# STM32H523 register map
File version: 1.3
CPU: CM33 r0p0, little endian, MPU, FPU, 4 interrupt priority bits
Registers are 32-bit, read-write, reset 0x0 unless marked. A register's access mark holds for its fields unless they carry their own. Offsets are from the block's base; [hi:lo] are bit positions; 'fields as' and 'values as' point back to an identical list.

## CRS — CRS address block description
Base 0x40006000
Same registers: CRS_S 0x50006000
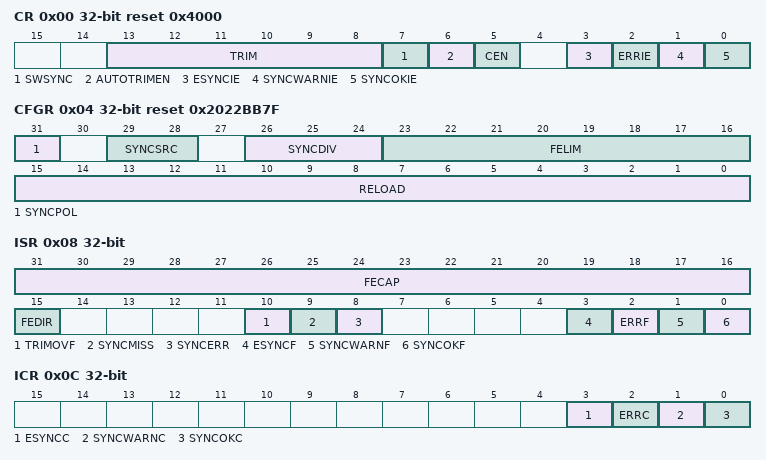
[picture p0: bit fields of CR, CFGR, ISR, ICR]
0x00 CR reset 0x4000 — CRS control register
  [13:8] TRIM — HSI48 oscillator smooth trimming
  [7] SWSYNC — Generate software SYNC event
    1=Sync (A software sync is generated)
  [6] AUTOTRIMEN — Automatic trimming enable
    0=Disabled (Automatic trimming disabled); 1=Enabled (Automatic trimming enabled)
  [5] CEN — Frequency error counter enable
    0=Disabled (Frequency error counter disabled); 1=Enabled (Frequency error counter enabled)
  [3] ESYNCIE — Expected SYNC interrupt enable
    0=Disabled (Interrupt disabled); 1=Enabled (Interrupt enabled)
  [2] ERRIE — Synchronization or trimming error interrupt enable
    values as ESYNCIE
  [1] SYNCWARNIE — SYNC warning interrupt enable
    values as ESYNCIE
  [0] SYNCOKIE — SYNC event OK interrupt enable
    values as ESYNCIE
0x04 CFGR reset 0x2022BB7F — CRS configuration register
  [31] SYNCPOL — SYNC polarity selection
    0=RisingEdge (SYNC active on rising edge); 1=FallingEdge (SYNC active on falling edge)
  [29:28] SYNCSRC — SYNC signal source selection
    0=GPIO_AF (GPIO AF (crs_sync_in_1) selected as SYNC signal source); 1=LSE (LSE (crs_sync_in_2) selected as SYNC signal source); 2=USB_SOF (USB SOF (crs_sync_in_3) selected as SYNC signal source)
  [26:24] SYNCDIV — SYNC divider
    0=Div1 (SYNC not divided); 1=Div2 (SYNC divided by 2); 2=Div4 (SYNC divided by 4); 3=Div8 (SYNC divided by 8); 4=Div16 (SYNC divided by 16); 5=Div32 (SYNC divided by 32); 6=Div64 (SYNC divided by 64); 7=Div128 (SYNC divided by 128)
  [23:16] FELIM — Frequency error limit
  [15:0] RELOAD — Counter reload value
0x08 ISR ro — CRS interrupt and status register
  [31:16] FECAP — Frequency error capture
  [15] FEDIR — Frequency error direction
    0=UpCounting (Error in up-counting direction); 1=DownCounting (Error in down-counting direction)
  [10] TRIMOVF — Trimming overflow or underflow
    0=NotSignaled (Signal not set); 1=Signaled (Signal set)
  [9] SYNCMISS — SYNC missed
    0=NotSignaled (Signal not set); 1=Signaled (Signal set)
  [8] SYNCERR — SYNC error
    0=NotSignaled (Signal not set); 1=Signaled (Signal set)
  [3] ESYNCF — Expected SYNC flag
    0=NotSignaled (Signal not set); 1=Signaled (Signal set)
  [2] ERRF — Error flag
    0=NotSignaled (Signal not set); 1=Signaled (Signal set)
  [1] SYNCWARNF — SYNC warning flag
    0=NotSignaled (Signal not set); 1=Signaled (Signal set)
  [0] SYNCOKF — SYNC event OK flag
    0=NotSignaled (Signal not set); 1=Signaled (Signal set)
0x0C ICR — CRS interrupt flag clear register
  [all] fields
    1=Clear flag
  [3] ESYNCC — Expected SYNC clear flag
  [2] ERRC — Error clear flag
  [1] SYNCWARNC — SYNC warning clear flag
  [0] SYNCOKC — SYNC event OK clear flag

## DCACHE — DCACHE register block
Base 0x40031400
Same registers: DCACHE_S 0x50031400
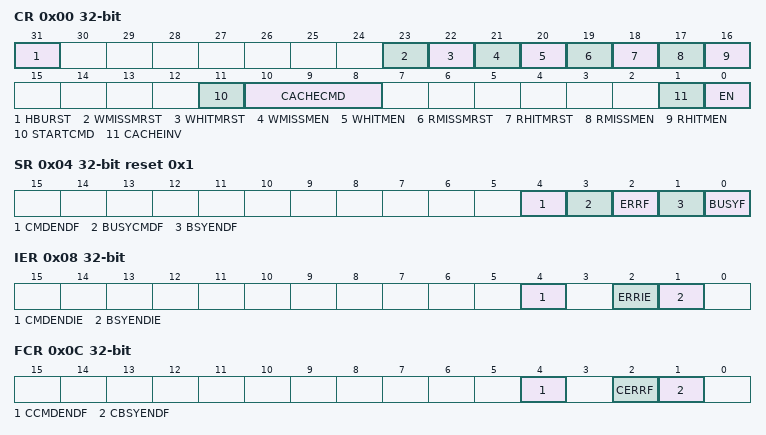
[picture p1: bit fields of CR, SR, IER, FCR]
0x00 CR — DCACHE control register
  [31] HBURST — output burst type for cache master port read accesses
  [23] WMISSMRST — write-miss monitor reset
  [22] WHITMRST — write-hit monitor reset
  [21] WMISSMEN — write-miss monitor enable
  [20] WHITMEN — write-hit monitor enable
  [19] RMISSMRST — read-miss monitor reset
  [18] RHITMRST — read-hit monitor reset
  [17] RMISSMEN — read-miss monitor enable
  [16] RHITMEN — read-hit monitor enable
  [11] STARTCMD wo — starts maintenance command (maintenance operation defined in CACHECMD).
  [10:8] CACHECMD — cache command maintenance operation (cleans and/or invalidates an address range)
  [1] CACHEINV wo — full cache invalidation
  [0] EN — enable
0x04 SR ro reset 0x1 — DCACHE status register
  [4] CMDENDF — command end flag
  [3] BUSYCMDF — command busy flag
  [2] ERRF — cache error flag
  [1] BSYENDF — full invalidate busy end flag
  [0] BUSYF — full invalidate busy flag
0x08 IER — DCACHE interrupt enable register
  [4] CMDENDIE — interrupt enable on command end
  [2] ERRIE — interrupt enable on cache error
  [1] BSYENDIE — interrupt enable on busy end
0x0C FCR wo — DCACHE flag clear register
  [4] CCMDENDF — clear command end flag
  [2] CERRF — clear cache error flag
  [1] CBSYENDF — clear full invalidate busy end flag
0x10 RHMONR ro — DCACHE read-hit monitor register
  [31:0] RHITMON — cache read-hit monitor counter
0x14 RMMONR ro — DCACHE read-miss monitor register
  [15:0] RMISSMON — cache read-miss monitor counter
0x20 WHMONR ro — DCACHE write-hit monitor register
  [31:0] WHITMON — cache write-hit monitor counter
0x24 WMMONR ro — DCACHE write-miss monitor register
  [15:0] WMISSMON — cache write-miss monitor counter
0x28 CMDRSADDRR — DCACHE command range start address register
  [31:4] CMDSTARTADDR — start address of range to which the cache maintenance command specified in DCACHE_CR.
0x2C CMDREADDRR — DCACHE command range end address register
  [31:4] CMDENDADDR — end address of range to which the cache maintenance command specified in DCACHE_CR.
